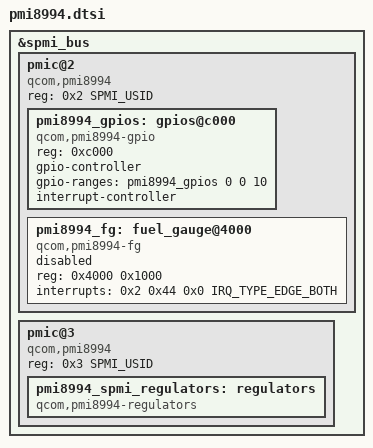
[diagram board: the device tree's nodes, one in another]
// SPDX-License-Identifier: GPL-2.0
#include <dt-bindings/interrupt-controller/irq.h>
#include <dt-bindings/spmi/spmi.h>

&spmi_bus {

	pmic@2 {
		compatible = "qcom,pmi8994", "qcom,spmi-pmic";
		reg = <0x2 SPMI_USID>;
		#address-cells = <1>;
		#size-cells = <0>;

		pmi8994_gpios: gpios@c000 {
			compatible = "qcom,pmi8994-gpio", "qcom,spmi-gpio";
			reg = <0xc000>;
			gpio-controller;
			gpio-ranges = <&pmi8994_gpios 0 0 10>;
			#gpio-cells = <2>;
			interrupt-controller;
			#interrupt-cells = <2>;
		};

		pmi8994_fg: fuel_gauge@4000 {
			compatible = "qcom,pmi8994-fg";
			status = "disabled";
			#address-cells = <1>;
			#size-cells = <0>;
			       //FG  //Charger
			reg = <0x4000 0x1000>;
			interrupts = <0x2 0x44 0x0 IRQ_TYPE_EDGE_BOTH>;
			interrupt-names = "mem-avail";
		};
	};

	pmic@3 {
		compatible = "qcom,pmi8994", "qcom,spmi-pmic";
		reg = <0x3 SPMI_USID>;
		#address-cells = <1>;
		#size-cells = <0>;

		pmi8994_spmi_regulators: regulators {
			compatible = "qcom,pmi8994-regulators";
			#address-cells = <1>;
			#size-cells = <1>;
		};
	};
};
